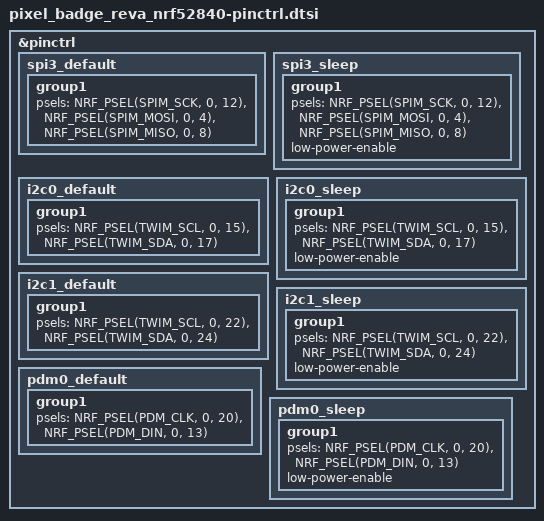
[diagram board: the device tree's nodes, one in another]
/* SPDX-License-Identifier: MIT */
#include <zephyr/dt-bindings/pinctrl/nrf-pinctrl.h>
&pinctrl {
	spi3_default: spi3_default {
		group1 {
			psels = <NRF_PSEL(SPIM_SCK, 0, 12)>, <NRF_PSEL(SPIM_MOSI, 0, 4)>, <NRF_PSEL(SPIM_MISO, 0, 8)>;
		};
	};
	spi3_sleep: spi3_sleep {
		group1 {
			psels = <NRF_PSEL(SPIM_SCK, 0, 12)>, <NRF_PSEL(SPIM_MOSI, 0, 4)>, <NRF_PSEL(SPIM_MISO, 0, 8)>;
			low-power-enable;
		};
	};
	i2c0_default: i2c0_default {
		group1 {
			psels = <NRF_PSEL(TWIM_SCL, 0, 15)>, <NRF_PSEL(TWIM_SDA, 0, 17)>;
		};
	};
	i2c0_sleep: i2c0_sleep {
		group1 {
			psels = <NRF_PSEL(TWIM_SCL, 0, 15)>, <NRF_PSEL(TWIM_SDA, 0, 17)>;
			low-power-enable;
		};
	};
	i2c1_default: i2c1_default {
		group1 {
			psels = <NRF_PSEL(TWIM_SCL, 0, 22)>, <NRF_PSEL(TWIM_SDA, 0, 24)>;
		};
	};
	i2c1_sleep: i2c1_sleep {
		group1 {
			psels = <NRF_PSEL(TWIM_SCL, 0, 22)>, <NRF_PSEL(TWIM_SDA, 0, 24)>;
			low-power-enable;
		};
	};
	pdm0_default: pdm0_default {
		group1 {
			psels = <NRF_PSEL(PDM_CLK, 0, 20)>, <NRF_PSEL(PDM_DIN, 0, 13)>;
		};
	};
	pdm0_sleep: pdm0_sleep {
		group1 {
			psels = <NRF_PSEL(PDM_CLK, 0, 20)>, <NRF_PSEL(PDM_DIN, 0, 13)>;
			low-power-enable;
		};
	};
};
